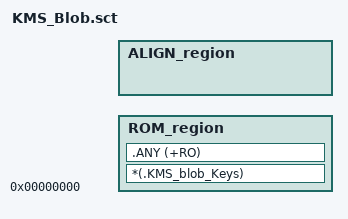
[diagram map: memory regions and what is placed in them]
; *************************************************************
; *** Scatter-Loading Description File generated by uVision ***
; *************************************************************

; *** regions needed by KMS_Blob project ***
LR_ROM (0x00000000) ALIGN(16) {
  ROM_region +0 {
  *(.KMS_blob_Keys)
  .ANY (+RO)
  }
  ALIGN_region +0 ALIGN(16) EMPTY(16) {
  }
} 
 
